AUTOSAR XML (schema 4-2-1)
package /RootP_ASWC_DISPATCH_CORE1_AppASILA
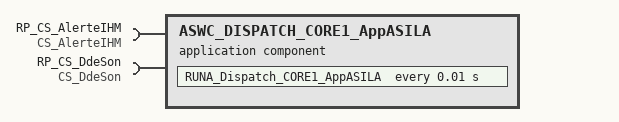
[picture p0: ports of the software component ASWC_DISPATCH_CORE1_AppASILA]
  application sw component type ASWC_DISPATCH_CORE1_AppASILA
    require port RP_CS_AlerteIHM: client-com-spec=Cmd, required-interface=CS_AlerteIHM
    require port RP_CS_DdeSon: client-com-spec=Cmd, required-interface=CS_DdeSon
    behavior IB_ASWC_DISPATCH_CORE1_AppASILA: handle-termination-and-restart=NO-SUPPORT
      timing event RUNA_Dispatch_Cyclic: start-on-event=RUNA_Dispatch_CORE1_AppASILA, period=0.01
      runnable RUNA_Dispatch_CORE1_AppASILA: can-be-invoked-concurrently=true
        sync call scp_AlerteIHM_Cmd: operation=RP_CS_AlerteIHM.Cmd, timeout=0.0
        sync call scp_DdeSon_Cmd: operation=RP_CS_DdeSon.Cmd, timeout=0.0
  swc implementation ASWC_DISPATCH_CORE1_AppASILA_Impl: programming-language=C, sw-version=1.0.0, vendor-id=0, behavior=IB_ASWC_DISPATCH_CORE1_AppASILA
    code-descriptors:
      code SRC: artifact-descriptors=autosar-engineering-object={short-label=EngObject, category=SWSRC}
    resource consumption Resources
      memory section CODE: sw-addrmethod=CODE_ASWC_DISPATCH_CORE1_AppASILA
  sw addr method CODE_ASWC_DISPATCH_CORE1_AppASILA: memory-allocation-keyword-policy=ADDR-METHOD-SHORT-NAME-AND-ALIGNMENT, section-type=CODE
